# N32G455 register map
Vendor: NSING TECHNOLOGIES PTE. LTD.; File version: 1.0
Registers are 32-bit, read-write, reset 0x0 unless marked. A register's access mark holds for its fields unless they carry their own. Offsets are from the block's base; [hi:lo] are bit positions; {n}, {i} and the like mark numbered series; 'fields as' and 'values as' point back to an identical list.

## RTC — Real time clock
Base 0x40002800
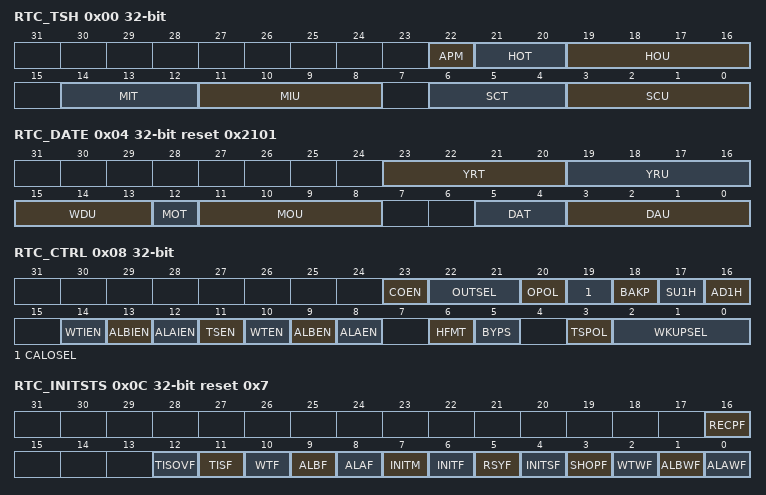
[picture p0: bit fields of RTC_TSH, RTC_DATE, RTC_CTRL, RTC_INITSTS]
0x00 RTC_TSH
  [22] APM, [21:20] HOT, [19:16] HOU, [14:12] MIT, [11:8] MIU, [6:4] SCT, [3:0] SCU
0x04 RTC_DATE reset 0x2101
  [23:20] YRT, [19:16] YRU, [15:13] WDU, [12] MOT, [11:8] MOU, [5:4] DAT, [3:0] DAU
0x08 RTC_CTRL (reset mask 0xFF7F67)
  [23] COEN, [22:21] OUTSEL, [20] OPOL, [19] CALOSEL, [18] BAKP, [17] SU1H, [16] AD1H, [14] WTIEN, [13] ALBIEN, [12] ALAIEN, [11] TSEN, [10] WTEN, [9] ALBEN, [8] ALAEN, [6] HFMT, [5] BYPS, [3] TSPOL, [2:0] WKUPSEL
0x0C RTC_INITSTS reset 0x7
  [16] RECPF, [12] TISOVF, [11] TISF, [10] WTF, [9] ALBF, [8] ALAF, [7] INITM, [6] INITF, [5] RSYF, [4] INITSF, [3] SHOPF, [2] WTWF, [1] ALBWF, [0] ALAWF
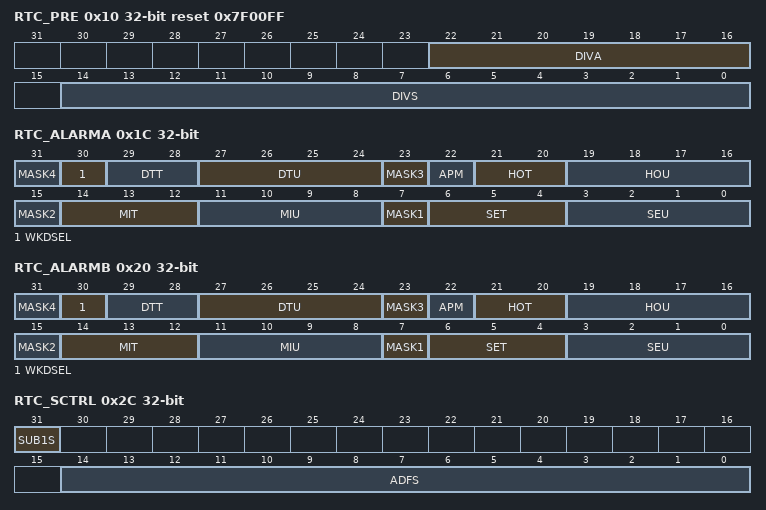
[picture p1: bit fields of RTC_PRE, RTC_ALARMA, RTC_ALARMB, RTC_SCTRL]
0x10 RTC_PRE reset 0x7F00FF
  [22:16] DIVA, [14:0] DIVS
0x14 RTC_WKUPT reset 0xFFFF
  [15:0] WKUPT
0x1C RTC_ALARMA
  [8n-1] MASK{n} (n=1..4), [30] WKDSEL, [29:28] DTT, [27:24] DTU, [22] APM, [21:20] HOT, [19:16] HOU, [14:12] MIT, [11:8] MIU, [6:4] SET, [3:0] SEU
0x20 RTC_ALARMB
  fields as RTC_ALARMA
0x24 RTC_WRP
  [7:0] PKEY
0x28 RTC_SUBS
  [15:0] SS
0x2C RTC_SCTRL
  [31] SUB1S, [14:0] ADFS
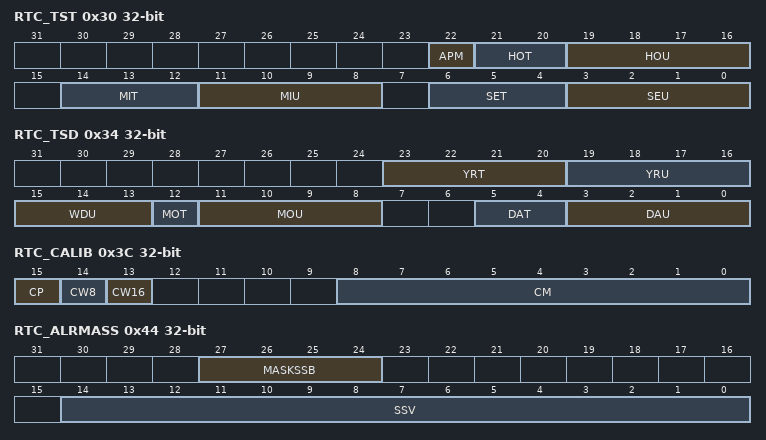
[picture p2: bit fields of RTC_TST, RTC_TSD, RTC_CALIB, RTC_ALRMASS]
0x30 RTC_TST (reset mask 0x7F)
  [22] APM, [21:20] HOT, [19:16] HOU, [14:12] MIT, [11:8] MIU, [6:4] SET, [3:0] SEU
0x34 RTC_TSD
  fields as RTC_DATE
0x38 RTC_TSSS
  [15:0] SSE
0x3C RTC_CALIB (reset mask 0xFF)
  [15] CP, [14] CW8, [13] CW16, [8:0] CM
0x44 RTC_ALRMASS
  [27:24] MASKSSB, [14:0] SSV
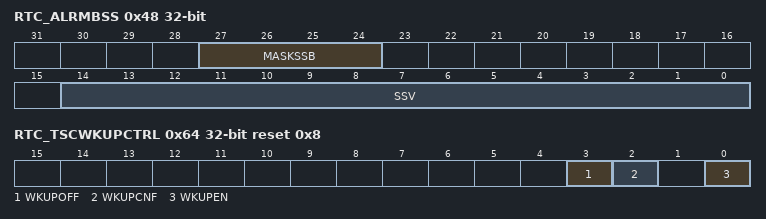
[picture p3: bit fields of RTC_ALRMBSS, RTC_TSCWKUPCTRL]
0x48 RTC_ALRMBSS
  [27:24] MASKSSB, [14:0] SSV
0x4C RTC_OPT
  [0] TYPE
0x64 RTC_TSCWKUPCTRL reset 0x8
  [3] WKUPOFF, [2] WKUPCNF, [0] WKUPEN
0x68 RTC_TSCWKUPCNT reset 0x2FE
  [13:0] CNT

## SDIO — Secure digital input/output interface
Base 0x40018000
0x00 SDIO_PWRCTRL
  [1:0] PWRCTRL
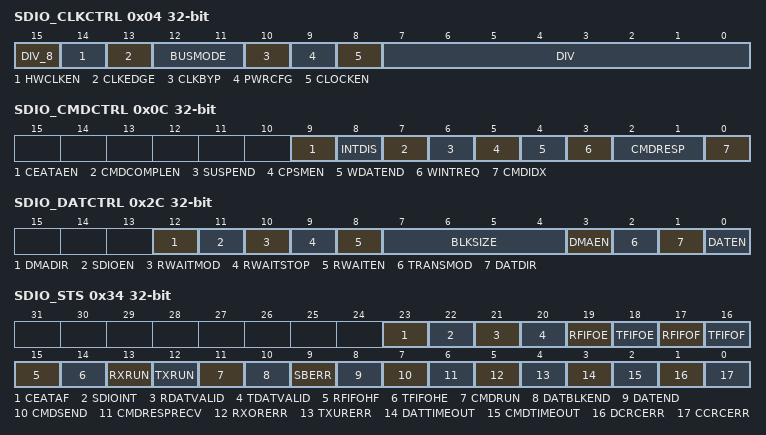
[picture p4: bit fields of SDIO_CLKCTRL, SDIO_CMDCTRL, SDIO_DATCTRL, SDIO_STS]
0x04 SDIO_CLKCTRL
  [15] DIV_8, [14] HWCLKEN, [13] CLKEDGE, [12:11] BUSMODE, [10] CLKBYP, [9] PWRCFG, [8] CLOCKEN, [7:0] DIV
0x08 SDIO_CMDARG
0x0C SDIO_CMDCTRL
  [9] CEATAEN, [8] INTDIS, [7] CMDCOMPLEN, [6] SUSPEND, [5] CPSMEN, [4] WDATEND, [3] WINTREQ, [2:1] CMDRESP, [0] CMDIDX
0x10 SDIO_CMDRESP
  [5:0] RESPCMDIDX
{0x10+4i} SDIO_RESP{i} (i=1..4)
  [31:0] CARDSTS{i}
0x24 SDIO_DATTIMEOUT
0x28 SDIO_DATLEN
  [24:0] DATLEN
0x2C SDIO_DATCTRL
  [12] DMADIR, [11] SDIOEN, [10] RWAITMOD, [9] RWAITSTOP, [8] RWAITEN, [7:4] BLKSIZE, [3] DMAEN, [2] TRANSMOD, [1] DATDIR, [0] DATEN
0x30 SDIO_DATCOUNT
  [24:0] DATCOUNT
0x34 SDIO_STS
  [23] CEATAF, [22] SDIOINT, [21] RDATVALID, [20] TDATVALID, [19] RFIFOE, [18] TFIFOE, [17] RFIFOF, [16] TFIFOF, [15] RFIFOHF, [14] TFIFOHE, [13] RXRUN, [12] TXRUN, [11] CMDRUN, [10] DATBLKEND, [9] SBERR, [8] DATEND, [7] CMDSEND, [6] CMDRESPRECV, [5] RXORERR, [4] TXURERR, [3] DATTIMEOUT, [2] CMDTIMEOUT, [1] DCRCERR, [0] CCRCERR
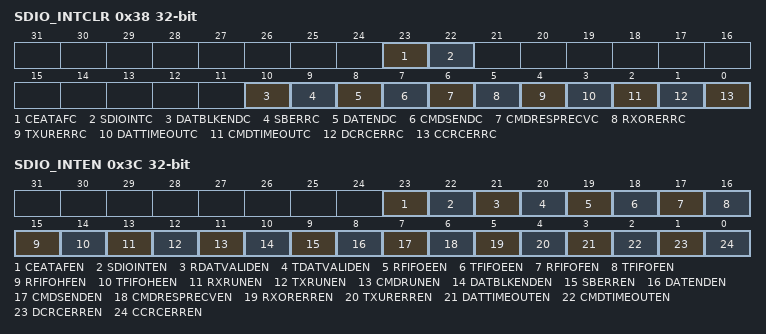
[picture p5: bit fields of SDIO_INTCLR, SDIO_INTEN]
0x38 SDIO_INTCLR
  [23] CEATAFC, [22] SDIOINTC, [10] DATBLKENDC, [9] SBERRC, [8] DATENDC, [7] CMDSENDC, [6] CMDRESPRECVC, [5] RXORERRC, [4] TXURERRC, [3] DATTIMEOUTC, [2] CMDTIMEOUTC, [1] DCRCERRC, [0] CCRCERRC
0x3C SDIO_INTEN
  [23] CEATAFEN, [22] SDIOINTEN, [21] RDATVALIDEN, [20] TDATVALIDEN, [19] RFIFOEEN, [18] TFIFOEEN, [17] RFIFOFEN, [16] TFIFOFEN, [15] RFIFOHFEN, [14] TFIFOHEEN, [13] RXRUNEN, [12] TXRUNEN, [11] CMDRUNEN, [10] DATBLKENDEN, [9] SBERREN, [8] DATENDEN, [7] CMDSENDEN, [6] CMDRESPRECVEN, [5] RXORERREN, [4] TXURERREN, [3] DATTIMEOUTEN, [2] CMDTIMEOUTEN, [1] DCRCERREN, [0] CCRCERREN
0x48 SDIO_FIFOCOUNT
  [23:0] FIFOCOUNT
0x80 SDIO_DATFIFO
  [31:0] FIFIDAT

## SPI1 — Serial peripheral interface
Base 0x40013000
Same registers: SPI2 0x40003800, SPI3 0x40003C00
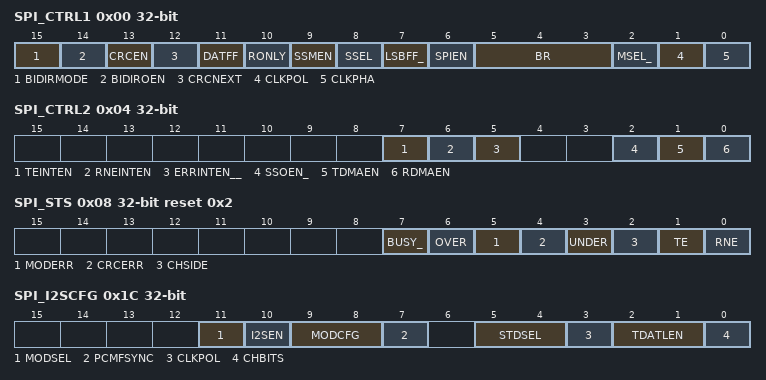
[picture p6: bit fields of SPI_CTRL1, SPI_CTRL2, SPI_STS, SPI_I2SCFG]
0x00 SPI_CTRL1
  [15] BIDIRMODE, [14] BIDIROEN, [13] CRCEN, [12] CRCNEXT, [11] DATFF, [10] RONLY, [9] SSMEN, [8] SSEL, [7] LSBFF_, [6] SPIEN, [5:3] BR, [2] MSEL_, [1] CLKPOL, [0] CLKPHA
0x04 SPI_CTRL2
  [7] TEINTEN, [6] RNEINTEN, [5] ERRINTEN__, [2] SSOEN_, [1] TDMAEN, [0] RDMAEN
0x08 SPI_STS reset 0x2
  [7] BUSY_, [6] OVER, [5] MODERR, [4] CRCERR, [3] UNDER, [2] CHSIDE, [1] TE, [0] RNE
0x0C SPI_DAT
  [15:0] DAT
0x10 SPI_CRCPOLY
  [15:0] CRCPOLY
0x14 SPI_CRCRDAT
  [15:0] CRCRDAT
0x18 SPI_CRCTDAT
  [15:0] CRCTDAT
0x1C SPI_I2SCFG
  [11] MODSEL, [10] I2SEN, [9:8] MODCFG, [7] PCMFSYNC, [5:4] STDSEL, [3] CLKPOL, [2:1] TDATLEN, [0] CHBITS
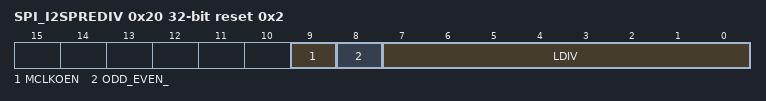
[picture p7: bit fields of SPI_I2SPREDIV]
0x20 SPI_I2SPREDIV reset 0x2
  [9] MCLKOEN, [8] ODD_EVEN_, [7:0] LDIV

## USART1 — Universal synchronous asynchronous receiver transmitter
Base 0x40013800
Same registers: USART2 0x40004400, USART3 0x40004800, UART4 0x40004C00, UART5 0x40005000, UART6 0x40015000, UART7 0x40015400
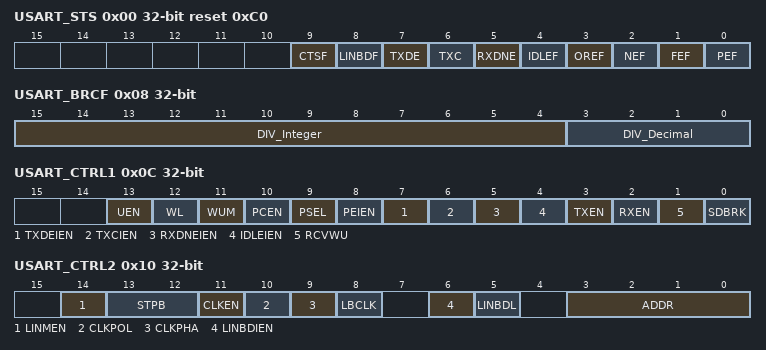
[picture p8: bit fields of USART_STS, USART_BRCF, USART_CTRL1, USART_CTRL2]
0x00 USART_STS reset 0xC0
  [9] CTSF, [8] LINBDF, [7] TXDE, [6] TXC, [5] RXDNE, [4] IDLEF, [3] OREF, [2] NEF, [1] FEF, [0] PEF
0x04 USART_DAT
  [8:0] DATV
0x08 USART_BRCF
  [15:4] DIV_Integer, [3:0] DIV_Decimal
0x0C USART_CTRL1
  [13] UEN, [12] WL, [11] WUM, [10] PCEN, [9] PSEL, [8] PEIEN, [7] TXDEIEN, [6] TXCIEN, [5] RXDNEIEN, [4] IDLEIEN, [3] TXEN, [2] RXEN, [1] RCVWU, [0] SDBRK
0x10 USART_CTRL2
  [14] LINMEN, [13:12] STPB, [11] CLKEN, [10] CLKPOL, [9] CLKPHA, [8] LBCLK, [6] LINBDIEN, [5] LINBDL, [3:0] ADDR
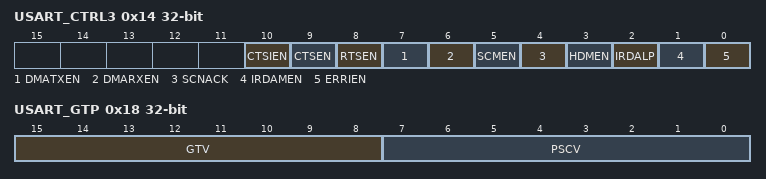
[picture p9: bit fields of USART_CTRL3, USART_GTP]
0x14 USART_CTRL3
  [10] CTSIEN, [9] CTSEN, [8] RTSEN, [7] DMATXEN, [6] DMARXEN, [5] SCMEN, [4] SCNACK, [3] HDMEN, [2] IRDALP, [1] IRDAMEN, [0] ERRIEN
0x18 USART_GTP
  [15:8] GTV, [7:0] PSCV

## USB — Universal serial bus full-speed device interface
Base 0x40005C00
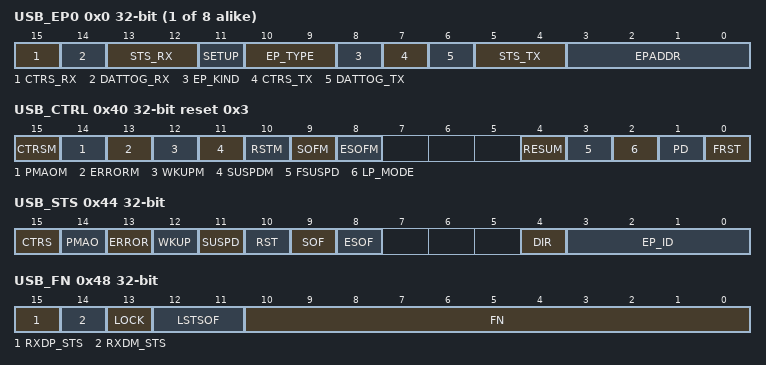
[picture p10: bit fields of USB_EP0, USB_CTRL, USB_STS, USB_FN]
{0x0+4i} USB_EP{i} (i=0..7)
  [15] CTRS_RX, [14] DATTOG_RX, [13:12] STS_RX, [11] SETUP, [10:9] EP_TYPE, [8] EP_KIND, [7] CTRS_TX, [6] DATTOG_TX, [5:4] STS_TX, [3:0] EPADDR
0x40 USB_CTRL reset 0x3
  [15] CTRSM, [14] PMAOM, [13] ERRORM, [12] WKUPM, [11] SUSPDM, [10] RSTM, [9] SOFM, [8] ESOFM, [4] RESUM, [3] FSUSPD, [2] LP_MODE, [1] PD, [0] FRST
0x44 USB_STS
  [15] CTRS, [14] PMAO, [13] ERROR, [12] WKUP, [11] SUSPD, [10] RST, [9] SOF, [8] ESOF, [4] DIR, [3:0] EP_ID
0x48 USB_FN
  [15] RXDP_STS, [14] RXDM_STS, [13] LOCK, [12:11] LSTSOF, [10:0] FN
0x4C USB_ADDR
  [6:0] ADDR
0x50 USB_BUFTAB
  [15:3] BUFTAB

## OPAMP — operational amplifier
Base 0x40002000
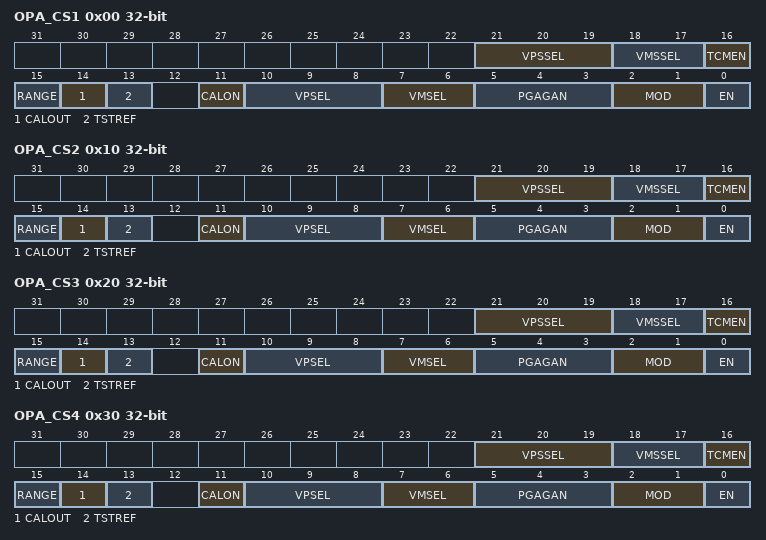
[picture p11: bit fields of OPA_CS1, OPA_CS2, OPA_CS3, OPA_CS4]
0x00 OPA_CS1
  [21:19] VPSSEL, [18:17] VMSSEL, [16] TCMEN, [15] RANGE, [14] CALOUT, [13] TSTREF, [11] CALON, [10:8] VPSEL, [7:6] VMSEL, [5:3] PGAGAN, [2:1] MOD, [0] EN
0x10 OPA_CS2
  fields as OPA_CS1
0x20 OPA_CS3
  fields as OPA_CS1
0x30 OPA_CS4
  fields as OPA_CS1
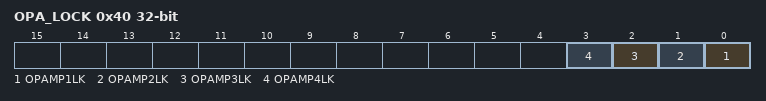
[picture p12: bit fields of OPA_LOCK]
0x40 OPA_LOCK
  [n-1] OPAMP{n}LK (n=1..4)

## COMP — comparator
Base 0x40002400
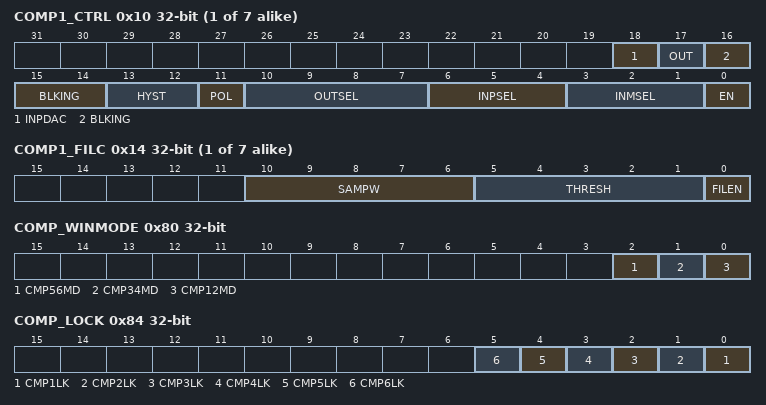
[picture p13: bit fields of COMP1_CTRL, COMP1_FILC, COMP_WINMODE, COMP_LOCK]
{0x0+0x10*i} COMP{i}_CTRL (i=1..7)
  [18] INPDAC, [17] OUT ro, [16:14] BLKING, [13:12] HYST, [11] POL, [10:7] OUTSEL, [6:4] INPSEL, [3:1] INMSEL, [0] EN
{0x4+0x10*i} COMP{i}_FILC (i=1..7)
  [10:6] SAMPW, [5:1] THRESH, [0] FILEN
{0x8+0x10*i} COMP{i}_FILP (i=1..7)
  [15:0] CLKPSC
0x80 COMP_WINMODE
  [2] CMP56MD, [1] CMP34MD, [0] CMP12MD
0x84 COMP_LOCK
  [n-1] CMP{n}LK (n=1..6)
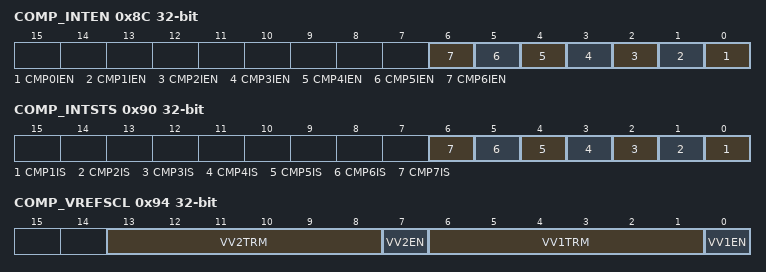
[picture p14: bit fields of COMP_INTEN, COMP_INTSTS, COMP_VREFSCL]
0x8C COMP_INTEN
  [n] CMP{n}IEN (n=0..6)
0x90 COMP_INTSTS
  [n-1] CMP{n}IS (n=1..7)
0x94 COMP_VREFSCL
  [13:8] VV2TRM, [7] VV2EN, [6:1] VV1TRM, [0] VV1EN

## TSC — touch screen control
Base 0x40003400
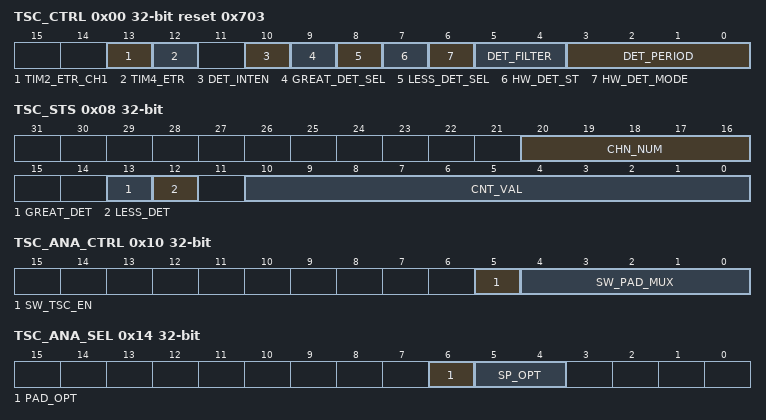
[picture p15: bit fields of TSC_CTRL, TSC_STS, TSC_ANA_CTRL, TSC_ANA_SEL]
0x00 TSC_CTRL reset 0x703
  [13] TIM2_ETR_CH1, [12] TIM4_ETR, [10] DET_INTEN, [9] GREAT_DET_SEL, [8] LESS_DET_SEL, [7] HW_DET_ST, [6] HW_DET_MODE, [5:4] DET_FILTER, [3:0] DET_PERIOD
0x04 TSC_CHNEN
  [23:0] CHN_SEL
0x08 TSC_STS
  [20:16] CHN_NUM, [13] GREAT_DET, [12] LESS_DET, [10:0] CNT_VAL
0x10 TSC_ANA_CTRL
  [5] SW_TSC_EN, [4:0] SW_PAD_MUX
0x14 TSC_ANA_SEL
  [6] PAD_OPT, [5:4] SP_OPT
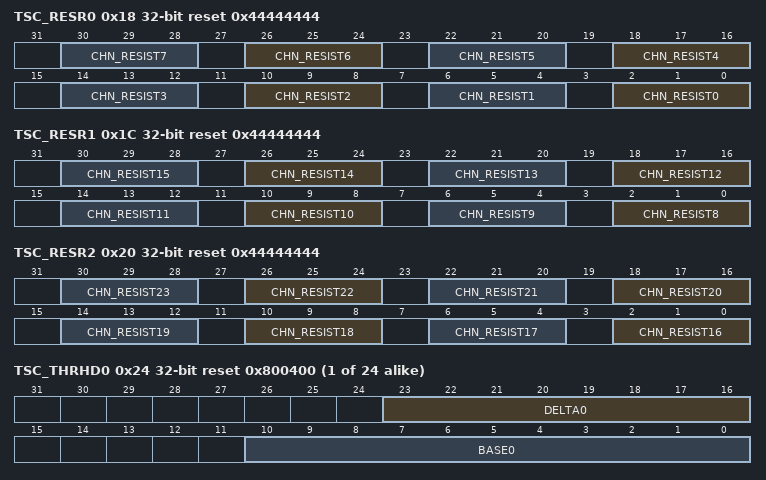
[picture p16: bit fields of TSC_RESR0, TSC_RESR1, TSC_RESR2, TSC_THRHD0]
0x18 TSC_RESR0 reset 0x44444444
  [4n+2:4n] CHN_RESIST{n} (n=0..7)
0x1C TSC_RESR1 reset 0x44444444
  [4n-30:4n-32] CHN_RESIST{n} (n=8..15)
0x20 TSC_RESR2 reset 0x44444444
  [4n-62:4n-64] CHN_RESIST{n} (n=16..23)
{0x24+4i} TSC_THRHD{i} reset 0x800400 (i=0..23)
  [23:16] DELTA{i}, [10:0] BASE{i}

## WWDG — window watchdog
Base 0x40002C00
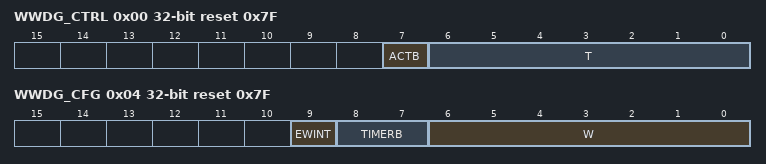
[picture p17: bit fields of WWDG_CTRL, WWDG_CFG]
0x00 WWDG_CTRL reset 0x7F
  [7] ACTB, [6:0] T
0x04 WWDG_CFG reset 0x7F
  [9] EWINT, [8:7] TIMERB, [6:0] W
0x08 WWDG_STS
  [0] EWINTF
